# iND83213A register map
Vendor: Indiemicro; Series: Rugby; File version: 1.0
CPU: CM0 r0p1, selectable endian, no MPU, no FPU, 4 interrupt priority bits
Registers are 32-bit, read-write, no defined reset value unless marked. A register's access mark holds for its fields unless they carry their own. Offsets are from the block's base; [hi:lo] are bit positions; {n}, {i} and the like mark numbered series.

## SPI — SPIM Interface registers
Base 0x50010700; register names take the prefix SPI_
0x00 SPIRXDATA — Serial Peripheral Rx Data Register
  [7:0] RXDATA ro — Rx Data buffer. Received Data Register. A read from this register will return data from current read pointer on the receive FIFO. A read from this register will increment the read pointer on the receive FIFO.
0x04 SPITXDATA — Serial Peripheral Tx Data Register
  [7:0] TXDATA wo — Tx Data buffer. Transmit Data Register. Used for data that is to be transmitted. A write to this register will place data into the transmit FIFO and increment the write pointer for the transmit FIFO.
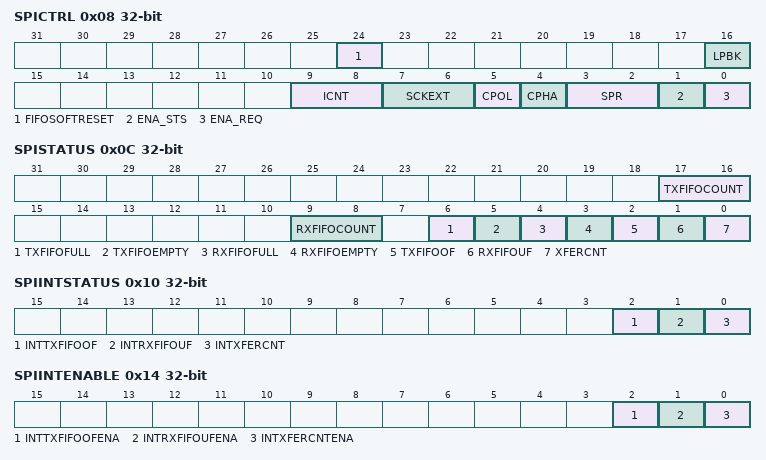
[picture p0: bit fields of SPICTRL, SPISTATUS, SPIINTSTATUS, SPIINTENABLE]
0x08 SPICTRL — Serial Peripheral Control Register
  [24] FIFOSOFTRESET wo — FIFO Soft Reset. FIFO Soft Reset bit (active high). Writing a one here will clear the FIFO pointers. This bit automatically clears to zero.
  [16] LPBK — Port wired-OR mode bit. 0x0: master_in = miso 0x1: master_in = mosi
  [9:8] ICNT — Interrupt counter bits. 0x0: Interrupt is set after every completed transfer 0x1: Interrupt is set after two completed transfers 0x2: Interrupt is set after three completed transfers 0x3: Interrupt is set after four completed transfers
  [7:6] SCKEXT — Extended clock divider. SPR - Standard Clock Rate Divider Select SPRE (SCKEXT) - Extended Clock Rate Select Bits {SPRE, SPR} = Clock Divide Result {00, 00}: System Clock / 2 {00, 01}: System Clock / 4 {00, 10}: System Clock / 8 {00, 11}: System Clock / 32 {01, 00}: System Clock / 64 {01, 01}: System Clock / 16 {01, 10}: System Clock / 128 {01, 11}: System Clock / 256 {10, 00}: System Clock / 512 {10, 01}: System Clock / 1024 {10, 10}: System Clock / 2048 {10, 11}: System Clock / 4096 {11, xx}: Reserved
  [5] CPOL — SPI clock polarity (Motorola SPI Frame Format). 0x0: The base value of the clock is zero 0x1: The base value of the clock is one
  [4] CPHA — SPI clock phase. 0x0: Data is captured on clock transition from base and data is propagated on the clock transition to base 0x1: Data is captured on clock transition to base and data is propagated on the clock transition from base
  [3:2] SPR — Standard clock divider selection. Please refer to SPRE register for system clock.
  [1] ENA_STS ro — SPI enable status. Status of SPI enable
  [0] ENA_REQ — SPI enable request. Enables the SPI interface. When SPI enable is deasserted the Tx and Rx FIFO's are still operable. Careful- If data is present in the Tx FIFO prior to enabling SPI, then once SPI is enabled it will begin transmitting the data present in the Tx FIFO.
0x0C SPISTATUS — Serial Peripheral Status Register
  [17:16] TXFIFOCOUNT ro — Transmit FIFO Count. Signal indicates active number of bytes in the FIFO. Increments on Push. Decrements on Pop.
  [9:8] RXFIFOCOUNT ro — Reception FIFO Count. Signal indicates active number of bytes in the FIFO. Increments on Push. Decrements on Pop.
  [6] TXFIFOFULL ro — Transmit FIFO full. 0x0: FIFO is NOT full 0x1: FIFO is full
  [5] TXFIFOEMPTY ro — Transmit FIFO empty. 0x0: FIFO is NOT empty 0x1: FIFO is empty
  [4] RXFIFOFULL ro — Reception FIFO full. 0x0: FIFO is NOT full 0x1: FIFO is full
  [3] RXFIFOEMPTY ro — Reception FIFO empty. 0x0: FIFO is NOT empty 0x1: FIFO is empty
  [2] TXFIFOOF ro — Transmit FIFO overflow. 0x0: overflow inactive 0x1: overflow active
  [1] RXFIFOUF ro — Reception FIFO underflow. 0x0: underflow inactive 0x1: underflow active
  [0] XFERCNT ro — Completed Transfer Count. Signal is set after a programmable amount of completed transfer. See SPI_CTRL register field ICNT.
0x10 SPIINTSTATUS — SPI Interrupt Status
  [2] INTTXFIFOOF ro — Transmit FIFO Overflow Interrupt. Interrupt is set when Transmit FIFO is full and a write transaction occurs. (WRITE COLLISION)
  [1] INTRXFIFOUF ro — Reception FIFO Underflow Interrupt. Interrupt is set when Receive FIFO is empty and a read transaction occurs. (READ COLLISION)
  [0] INTXFERCNT ro — SPI Transfer Count Interrupt. Interrupt is set after a programmable amount of completed transfer. See SPI_CTRL register field ICNT.
0x14 SPIINTENABLE — SPI Interrupt Enable
  [2] INTTXFIFOOFENA — Transmit FIFO Overflow Interrupt Enable.
  [1] INTRXFIFOUFENA — Reception FIFO Underflow Interrupt Enable.
  [0] INTXFERCNTENA — SPI Transfer Count Interrupt Enable.
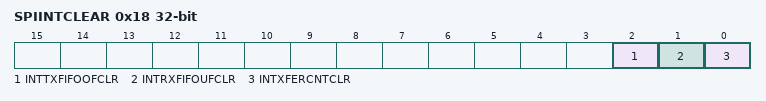
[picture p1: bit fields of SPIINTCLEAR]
0x18 SPIINTCLEAR — SPI Interrupt Clear
  [2] INTTXFIFOOFCLR wo — Transmit FIFO Overflow Interrupt. Autoclear: includes a synchronous reset signal which clears the register on the cycle following write.
  [1] INTRXFIFOUFCLR wo — Reception FIFO Underflow Interrupt. Autoclear: includes a synchronous reset signal which clears the register on the cycle following write.
  [0] INTXFERCNTCLR wo — SPI Transfer Count Interrupt. Autoclear: includes a synchronous reset signal which clears the register on the cycle following write.
